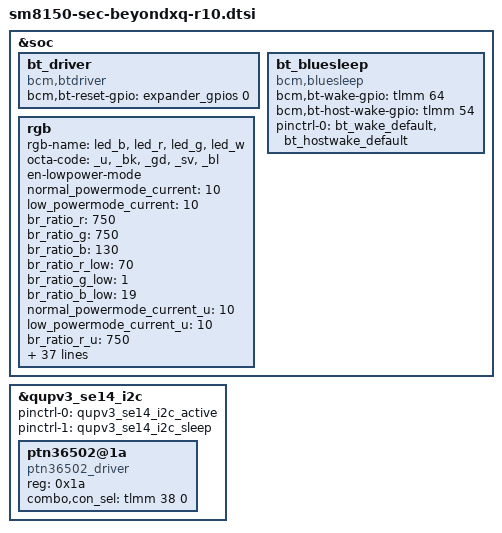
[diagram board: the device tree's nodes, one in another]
/* Copyright (c) 2016-2017, The Linux Foundation. All rights reserved.
 *
 * This program is free software; you can redistribute it and/or modify
 * it under the terms of the GNU General Public License version 2 and
 * only version 2 as published by the Free Software Foundation.
 *
 * This program is distributed in the hope that it will be useful,
 * but WITHOUT ANY WARRANTY; without even the implied warranty of
 * MERCHANTABILITY or FITNESS FOR A PARTICULAR PURPOSE.  See the
 * GNU General Public License for more details.
 */

#include "sm8150-sec-beyondxq-common.dtsi"
#include "sm8150-sec-beyondxq-optics-r09.dtsi"

&soc {
	bt_driver {
		compatible = "bcm,btdriver";  //bt_en
		pinctrl-names = "default";
		bcm,bt-reset-gpio = <&expander_gpios 0 GPIO_ACTIVE_HIGH>;
		status = "okay";
	};

	bt_bluesleep {
		compatible = "bcm,bluesleep";
		bcm,bt-wake-gpio = <&tlmm 64 0>;
		bcm,bt-host-wake-gpio = <&tlmm 54 0>;
		pinctrl-names = "default";
		pinctrl-0 = <&bt_wake_default &bt_hostwake_default>;
		status = "okay";
	};

	rgb {
		device_type = "star1";
		rgb-name = "led_b", "led_r", "led_g", "led_w";
		octa-code = "_u", "_bk", "_gd", "_sv", "_bl";

		en-lowpower-mode;

		normal_powermode_current = <10>;
		low_powermode_current = <10>;
		br_ratio_r = <750>;
		br_ratio_g = <750>;
		br_ratio_b = <130>;
		br_ratio_r_low = <70>;
		br_ratio_g_low = <1>;
		br_ratio_b_low = <19>;

		normal_powermode_current_u = <10>;
		low_powermode_current_u = <10>;
		br_ratio_r_u = <750>;
		br_ratio_g_u = <370>;
		br_ratio_b_u = <130>;
		br_ratio_r_low_u = <70>;
		br_ratio_g_low_u = <1>;
		br_ratio_b_low_u = <19>;

		normal_powermode_current_bk = <10>;
		low_powermode_current_bk = <10>;
		br_ratio_r_bk = <750>;
		br_ratio_g_bk = <70>;
		br_ratio_b_bk = <130>;
		br_ratio_r_low_bk = <70>;
		br_ratio_g_low_bk = <1>;
		br_ratio_b_low_bk = <19>;

		normal_powermode_current_gd = <10>;
		low_powermode_current_gd = <10>;
		br_ratio_r_gd = <750>;
		br_ratio_g_gd = <70>;
		br_ratio_b_gd = <130>;
		br_ratio_r_low_gd = <70>;
		br_ratio_g_low_gd = <1>;
		br_ratio_b_low_gd = <19>;

		normal_powermode_current_sv = <10>;
		low_powermode_current_sv = <10>;
		br_ratio_r_sv = <750>;
		br_ratio_g_sv = <70>;
		br_ratio_b_sv = <130>;
		br_ratio_r_low_sv = <70>;
		br_ratio_g_low_sv = <1>;
		br_ratio_b_low_sv = <19>;

		normal_powermode_current_bl = <10>;
		low_powermode_current_bl = <10>;
		br_ratio_r_bl = <750>;
		br_ratio_g_bl = <70>;
		br_ratio_b_bl = <130>;
		br_ratio_r_low_bl = <70>;
		br_ratio_g_low_bl = <1>;
		br_ratio_b_low_bl = <19>;
	};
};

&qupv3_se14_i2c {
	status = "ok";

	pinctrl-names = "default", "sleep";
	pinctrl-0 = <&qupv3_se14_i2c_active>;
	pinctrl-1 = <&qupv3_se14_i2c_sleep>;

	ptn36502@1a {
		compatible = "ptn36502_driver";
		reg = <0x1a>;
		combo,con_sel = <&tlmm 38 0>;
	};
};

